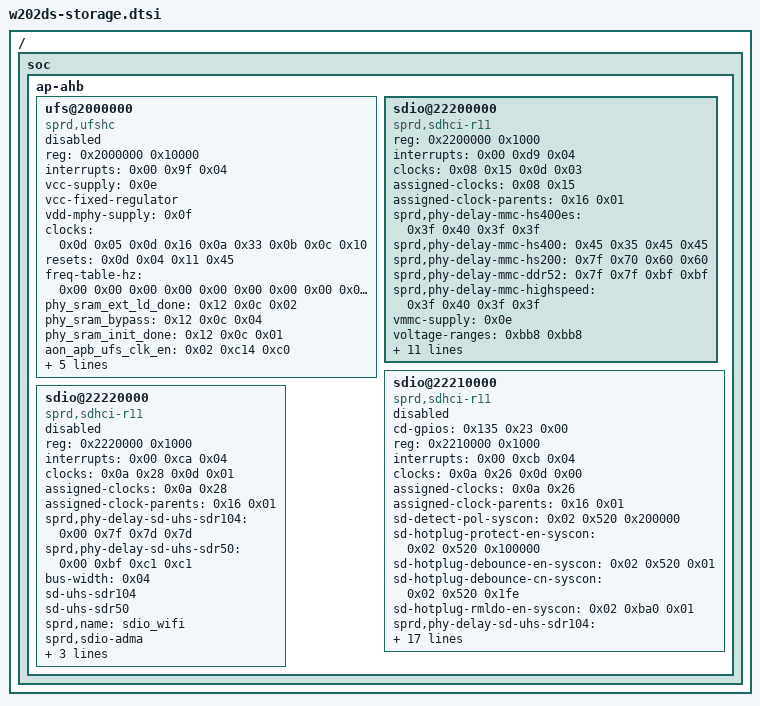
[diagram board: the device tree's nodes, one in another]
// W202DS Server hardware layout; split from the validated imported tree.
/ {
	soc {
		ap-ahb {
			ufs@2000000 {
				compatible = "sprd,ufshc";
				reg = <0x2000000 0x10000>;
				interrupts = <0x00 0x9f 0x04>;
				vcc-supply = <0x0e>;
				vcc-fixed-regulator;
				vdd-mphy-supply = <0x0f>;
				clock-names = "ufs_eb", "ufs_cfg_eb", "ufs_hclk", "ufs_hclk_source", "ufs_rco_100M";
				clocks = <0x0d 0x05 0x0d 0x16 0x0a 0x33 0x0b 0x0c 0x10>;
				reset-names = "ufs_soft_rst", "ufsdev_soft_rst";
				resets = <0x0d 0x04 0x11 0x45>;
				freq-table-hz = <0x00 0x00 0x00 0x00 0x00 0x00 0x00 0x00 0x00 0x00>;
				phy_sram_ext_ld_done = <0x12 0x0c 0x02>;
				phy_sram_bypass = <0x12 0x0c 0x04>;
				phy_sram_init_done = <0x12 0x0c 0x01>;
				aon_apb_ufs_clk_en = <0x02 0xc14 0xc0>;
				ufsdev_refclk_en = <0x02 0xce8 0x02>;
				usb31pllv_ref2mphy_en = <0x02 0xcfc 0x01>;
				nvmem-cells = <0x13 0x14>;
				nvmem-cell-names = "ufs_cali_lane1", "ufs_cali_lane0";
				status = "disabled";
				phandle = <0x142>;
			};
			sdio@22200000 {
				compatible = "sprd,sdhci-r11";
				reg = <0x2200000 0x1000>;
				interrupts = <0x00 0xd9 0x04>;
				clock-names = "sdio", "enable";
				clocks = <0x08 0x15 0x0d 0x03>;
				assigned-clocks = <0x08 0x15>;
				assigned-clock-parents = <0x16 0x01>;
				status = "okay";
				sprd,phy-delay-mmc-hs400es = <0x3f 0x40 0x3f 0x3f>;
				sprd,phy-delay-mmc-hs400 = <0x45 0x35 0x45 0x45>;
				sprd,phy-delay-mmc-hs200 = <0x7f 0x70 0x60 0x60>;
				sprd,phy-delay-mmc-ddr52 = <0x7f 0x7f 0xbf 0xbf>;
				sprd,phy-delay-mmc-highspeed = <0x3f 0x40 0x3f 0x3f>;
				vmmc-supply = <0x0e>;
				voltage-ranges = <0xbb8 0xbb8>;
				bus-width = <0x08>;
				non-removable;
				cap-mmc-hw-reset;
				mmc-hs400-enhanced-strobe;
				mmc-hs400-1_8v;
				mmc-hs200-1_8v;
				mmc-ddr-1_8v;
				sprd,name = "sdio_emmc";
				sprd,sdio-adma;
				no-sdio;
				no-sd;
				phandle = <0x144>;
			};
			sdio@22210000 {
				cd-gpios = <0x135 0x23 0x00>;
				compatible = "sprd,sdhci-r11";
				reg = <0x2210000 0x1000>;
				interrupts = <0x00 0xcb 0x04>;
				clock-names = "sdio", "enable";
				clocks = <0x0a 0x26 0x0d 0x00>;
				assigned-clocks = <0x0a 0x26>;
				assigned-clock-parents = <0x16 0x01>;
				status = "disabled";
				sd-detect-pol-syscon = <0x02 0x520 0x200000>;
				sd-hotplug-protect-en-syscon = <0x02 0x520 0x100000>;
				sd-hotplug-debounce-en-syscon = <0x02 0x520 0x01>;
				sd-hotplug-debounce-cn-syscon = <0x02 0x520 0x1fe>;
				sd-hotplug-rmldo-en-syscon = <0x02 0xba0 0x01>;
				sprd,phy-delay-sd-uhs-sdr104 = <0x00 0xc3 0xca 0xca>;
				sprd,phy-delay-sd-uhs-sdr50 = <0x00 0x7f 0x4d 0x4d>;
				sprd,phy-delay-sd-highspeed = <0x7f 0x43 0x43 0x43>;
				sprd,phy-delay-legacy = <0x00 0x00 0x00 0x00>;
				vmmc-supply = <0x17>;
				vqmmc-supply = <0x18>;
				voltage-ranges = <0xbb8 0xbb8>;
				bus-width = <0x04>;
				sd-uhs-sdr104;
				sd-uhs-sdr50;
				sprd,name = "sdio_sd";
				sprd,sdio-adma;
				no-sdio;
				no-mmc;
				non-removable;
				phandle = <0x145>;
			};
			sdio@22220000 {
				compatible = "sprd,sdhci-r11";
				reg = <0x2220000 0x1000>;
				interrupts = <0x00 0xca 0x04>;
				clock-names = "sdio", "enable";
				clocks = <0x0a 0x28 0x0d 0x01>;
				assigned-clocks = <0x0a 0x28>;
				assigned-clock-parents = <0x16 0x01>;
				status = "disabled";
				sprd,phy-delay-sd-uhs-sdr104 = <0x00 0x7f 0x7d 0x7d>;
				sprd,phy-delay-sd-uhs-sdr50 = <0x00 0xbf 0xc1 0xc1>;
				bus-width = <0x04>;
				sd-uhs-sdr104;
				sd-uhs-sdr50;
				sprd,name = "sdio_wifi";
				sprd,sdio-adma;
				no-sd;
				no-mmc;
				non-removable;
				phandle = <0x146>;
			};
		};
	};
	__symbols__ {
		ufs = "/soc/ap-ahb/ufs@2000000";
		sdio3 = "/soc/ap-ahb/sdio@22200000";
		sdio0 = "/soc/ap-ahb/sdio@22210000";
		sdio1 = "/soc/ap-ahb/sdio@22220000";
	};
};
